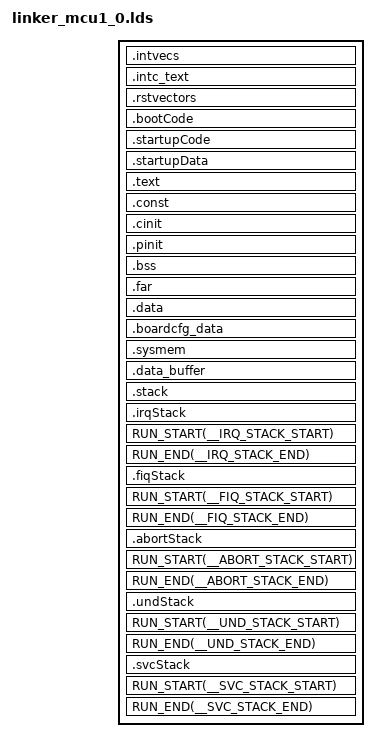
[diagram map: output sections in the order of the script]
/*
 * WWDT Example
 *
 * Windowed Watchdog Timer (WWDT) Example Application
 *
 *  Copyright (c) Texas Instruments Incorporated 2020
 *
 *  Redistribution and use in source and binary forms, with or without
 *  modification, are permitted provided that the following conditions
 *  are met:
 *
 *    Redistributions of source code must retain the above copyright
 *    notice, this list of conditions and the following disclaimer.
 *
 *    Redistributions in binary form must reproduce the above copyright
 *    notice, this list of conditions and the following disclaimer in the
 *    documentation and/or other materials provided with the
 *    distribution.
 *
 *    Neither the name of Texas Instruments Incorporated nor the names of
 *    its contributors may be used to endorse or promote products derived
 *    from this software without specific prior written permission.
 *
 *  THIS SOFTWARE IS PROVIDED BY THE COPYRIGHT HOLDERS AND CONTRIBUTORS
 *  "AS IS" AND ANY EXPRESS OR IMPLIED WARRANTIES, INCLUDING, BUT NOT
 *  LIMITED TO, THE IMPLIED WARRANTIES OF MERCHANTABILITY AND FITNESS FOR
 *  A PARTICULAR PURPOSE ARE DISCLAIMED. IN NO EVENT SHALL THE COPYRIGHT
 *  OWNER OR CONTRIBUTORS BE LIABLE FOR ANY DIRECT, INDIRECT, INCIDENTAL,
 *  SPECIAL, EXEMPLARY, OR CONSEQUENTIAL DAMAGES (INCLUDING, BUT NOT
 *  LIMITED TO, PROCUREMENT OF SUBSTITUTE GOODS OR SERVICES; LOSS OF USE,
 *  DATA, OR PROFITS; OR BUSINESS INTERRUPTION) HOWEVER CAUSED AND ON ANY
 *  THEORY OF LIABILITY, WHETHER IN CONTRACT, STRICT LIABILITY, OR TORT
 *  (INCLUDING NEGLIGENCE OR OTHERWISE) ARISING IN ANY WAY OUT OF THE USE
 *  OF THIS SOFTWARE, EVEN IF ADVISED OF THE POSSIBILITY OF SUCH DAMAGE.
 *
 */

/*----------------------------------------------------------------------------*/
/* File: linker_mcu1_0.lds                                                    */
/* Description:																  */
/*    Link command file for J721E R5F MCU 0 view							  */
/*----------------------------------------------------------------------------*/
/* Linker Settings                                                            */
/* Standard linker options													  */
--retain="*(.bootCode)"
--retain="*(.startupCode)"
--retain="*(.startupData)"
--retain="*(.intvecs)"
--retain="*(.intc_text)"
--retain="*(.rstvectors)"
--retain="*(.irqStack)"
--retain="*(.fiqStack)"
--retain="*(.abortStack)"
--retain="*(.undStack)"
--retain="*(.svcStack)"
--fill_value=0
--stack_size=0x2000
--heap_size=0x1000
--entry_point=_resetvectors     /* Default C RTS boot.asm   */

-stack  0x2000                              /* SOFTWARE STACK SIZE           */
-heap   0x2000                              /* HEAP AREA SIZE                */

/* Stack Sizes for various modes */
__IRQ_STACK_SIZE = 0x1000;
__FIQ_STACK_SIZE = 0x1000;
__ABORT_STACK_SIZE = 0x1000;
__UND_STACK_SIZE = 0x1000;
__SVC_STACK_SIZE = 0x1000;

/* Memory Map */
MEMORY
{
    VECTORS (X)             : origin=0x41C7F000 length=0x1000
    /*  Reset Vectors base address(RESET_VECTORS) should be 64 bytes aligned  */
    RESET_VECTORS (X)       : origin=0x41C00000 length=0x100
    /* MCU0_R5F_0 local view */
    MCU0_R5F_TCMA_SBL_RSVD (X)  : origin=0x0        length=0x100
    MCU0_R5F_TCMA (X)       : origin=0x100      length=0x8000 - 0x100
    MCU0_R5F_TCMB0 (RWIX)   : origin=0x41010000 length=0x8000

    /* MCU0_R5F_1 SoC view */
    MCU0_R5F1_ATCM (RWIX)   : origin=0x41400000 length=0x8000
    MCU0_R5F1_BTCM (RWIX)   : origin=0x41410000 length=0x8000

    /* MCU0 share locations */
    OCMRAM  (RWIX)          : origin=0x41C00100 length=0x80000 - 0x1100      /* ~510KB */

    /* j721e MCMS3 locations */
    /* j721e Reserved Memory for ARM Trusted Firmware */
    MSMC3_ARM_FW   (RWIX)   : origin=0x70000000 length=0x40000         /* 256KB */
    MSMC3   (RWIX)          : origin=0x70040000 length=0x7B0000        /* 8MB - 320KB */
    /* j721e Reserved Memory for DMSC Firmware */
    MSMC3_DMSC_FW  (RWIX)   : origin=0x707F0000 length=0x10000         /* 64KB */

    DDR0    (RWIX)          : origin=0x80000000 length=0x80000000      /* 2GB */
}

/* Section Configuration */
SECTIONS
{
    /* 'intvecs' and 'intc_text' sections shall be placed within */
    /* a range of +\- 16 MB */
    .intvecs       : {} palign(8)      > VECTORS
    .intc_text     : {} palign(8)      > VECTORS
    .rstvectors    : {} palign(8)      > RESET_VECTORS
    .bootCode      : {} palign(8)      > MSMC3
    .startupCode   : {} palign(8)      > MSMC3
    .startupData   : {} palign(8)      > MSMC3, type = NOINIT
    .text          : {} palign(8)      > DDR0
    .const         : {} palign(8)      > DDR0
    .cinit         : {} palign(8)      > DDR0
    .pinit         : {} palign(8)      > DDR0
    .bss           : {} align(4)       > DDR0
    .far           : {} align(4)       > DDR0
    .data          : {} palign(128)    > DDR0
    .boardcfg_data : {} palign(128)    > MSMC3
    .sysmem        : {}                > DDR0
    .data_buffer   : {} palign(128)    > DDR0

    /* USB or any other LLD buffer for benchmarking */
    .benchmark_buffer (NOLOAD) {} ALIGN (8) > DDR0

    .stack      : {} align(4)       > DDR0  (HIGH)
    .irqStack   : {. = . + __IRQ_STACK_SIZE;} align(4)      > DDR0  (HIGH)
    RUN_START(__IRQ_STACK_START)
    RUN_END(__IRQ_STACK_END)
    .fiqStack   : {. = . + __FIQ_STACK_SIZE;} align(4)      > DDR0  (HIGH)
    RUN_START(__FIQ_STACK_START)
    RUN_END(__FIQ_STACK_END)
    .abortStack : {. = . + __ABORT_STACK_SIZE;} align(4)    > DDR0  (HIGH)
    RUN_START(__ABORT_STACK_START)
    RUN_END(__ABORT_STACK_END)
    .undStack   : {. = . + __UND_STACK_SIZE;} align(4)      > DDR0  (HIGH)
    RUN_START(__UND_STACK_START)
    RUN_END(__UND_STACK_END)
    .svcStack   : {. = . + __SVC_STACK_SIZE;} align(4)      > DDR0  (HIGH)
    RUN_START(__SVC_STACK_START)
    RUN_END(__SVC_STACK_END)
}
